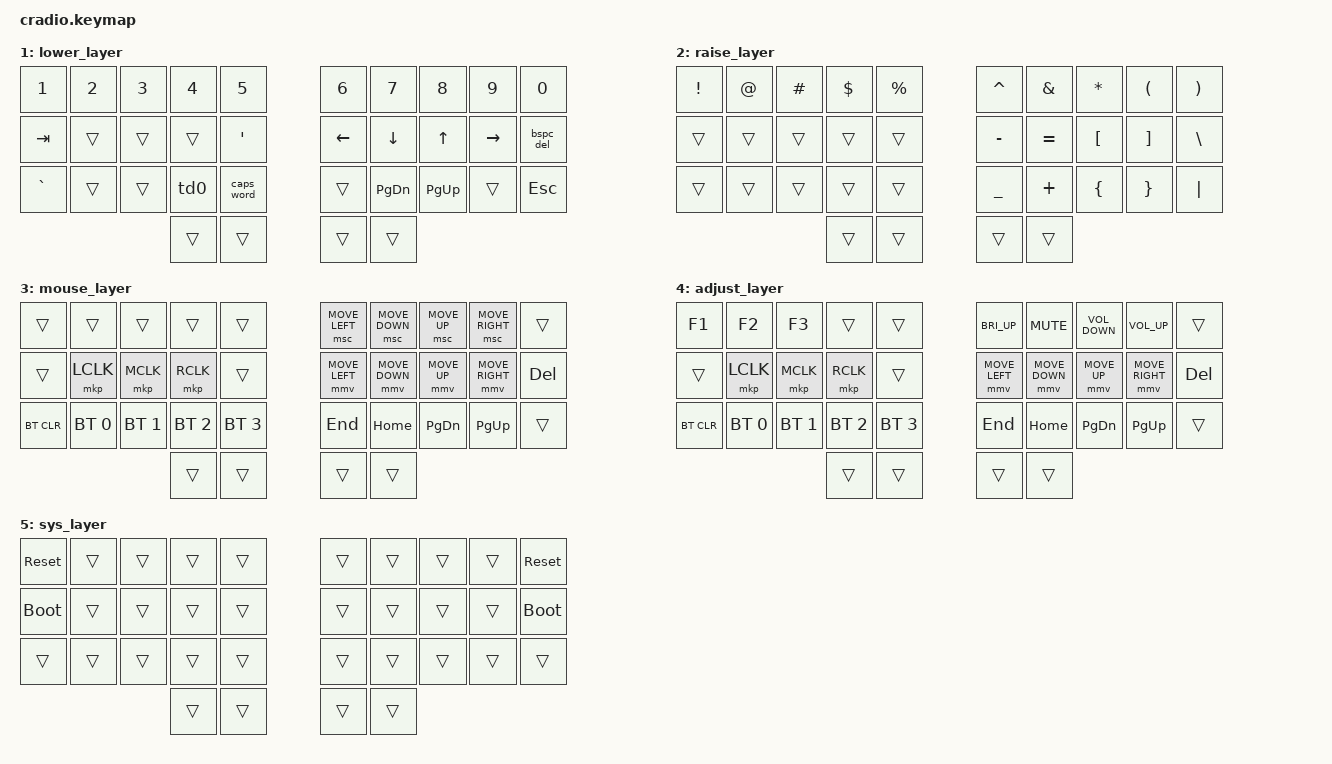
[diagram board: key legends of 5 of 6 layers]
// Copyright (c) 2022 The ZMK Contributors
// SPDX-License-Identifier: MIT

#include <behaviors.dtsi>
#include <dt-bindings/zmk/keys.h>
#include <dt-bindings/zmk/bt.h>
#include <dt-bindings/zmk/mouse.h>
#include <behaviors/mouse_keys.dtsi>

// Home row mods macro
#define HRML(k1,k2,k3,k4) &hm LCTRL k1  &hm LALT k2  &hm LGUI k3  &hm LSHIFT k4
#define HRMR(k1,k2,k3,k4) &hm RSHIFT k1  &hm RGUI k2  &hm RALT k3  &bhm RCTRL k4

/ {
    
    conditional_layers {
      compatible = "zmk,conditional-layers";
      tri_layer {
        if-layers = <1 2>;
        then-layer = <3>;
      };
    };

    combos {
      compatible = "zmk,combos";

      to_normal_keys_layer {
        bindings = <&tog 5>;
        key-positions = <17 18>; // g + h
      };

      // to_adjust_2_layer {
      //   bindings = <&mo 4>;
      //   key-positions = <40 34>;  // raise + z
      // };
    };

    behaviors {
      bhm: balanced_homerow_mods { // suitable for fast shortcuts/navigating
        compatible = "zmk,behavior-hold-tap";
        #binding-cells = <2>;
        tapping-term-ms = <200>;    // <---[[moderate duration]]
        quick-tap-ms = <0>;
        flavor = "balanced"; // The 'balanced' flavor will trigger the hold behavior when the tapping-term-ms has expired or another key is pressed and released.
        bindings = <&kp>, <&kp>;
      };

      hm: homerow_mods { // suitable for fast typing as this behavior prefers tap over than hold
        compatible = "zmk,behavior-hold-tap";
        #binding-cells = <2>;
        tapping-term-ms = <200>;
        quick-tap-ms = <0>;
        flavor = "tap-preferred"; // The 'tap-preferred' flavor triggers the hold behavior when the tapping-term-ms has expired. Pressing another key within tapping-term-ms does not affect the decision.
        bindings = <&kp>, <&kp>;
      };

      td0: tap_dance_0 {
        compatible = "zmk,behavior-tap-dance";
        #binding-cells = <0>;
        tapping-term-ms = <200>;
        bindings = <&kp ESC>, <&kp GLOBE>; // press once for Esc, and double for Globe/fn key
      };

      td1: tap_dance_1 {
        compatible = "zmk,behavior-tap-dance";
        #binding-cells = <0>;
        tapping-term-ms = <200>;
        bindings = <&mo 2>, <&mo 4>; // press once for "raise_layer", and double for "adjust_layer"
      };

      bspc_del: backspace_delete {
        compatible = "zmk,behavior-mod-morph";
        #binding-cells = <0>;
        bindings = <&kp BACKSPACE>, <&kp DELETE>;
        mods = <(MOD_LSFT|MOD_RSFT)>;
        keep-mods = <(MOD_RSFT)>;
      };

    };

    keymap {
        compatible = "zmk,keymap";
        default_layer {
            bindings = <
        //╭──────────┬──────────┬──────────┬──────────┬──────────╮   ╭──────────┬──────────┬──────────┬──────────┬──────────╮
        //│  Q       │  W       │  E       │  R       │  T       │   │  Y       │  U       │  I       │  O       │  P       │
            &kp Q      &kp W      &kp E      &kp R      &kp T          &kp Y      &kp U      &kp I      &kp O      &kp P
        //├──────────┼──────────┼──────────┼──────────┼──────────┤   ├──────────┼──────────┼──────────┼──────────┼──────────┤
        //│  A       │  S       │  D       │  F       │  G       │   │  H       │  J       │  K       │  L       │ ' "      │
            HRML(A,        S,         D,         F)     &kp G          &kp H      HRMR(J,        K,         L,        SQT)
        //├──────────┼──────────┼──────────┼──────────┼──────────┤   ├──────────┼──────────┼──────────┼──────────┼──────────┤
        //│  Z       │  X       │  C       │  V       │  B       │   │  N       │  M       │ , <      │ . >      │ / ?      │
            &kp Z      &kp X      &kp C      &kp V      &kp B          &kp N      &kp M      &kp COMMA  &kp DOT    &hm CAPS FSLH
        //╰──────────┴──────────┴──────────┼──────────┼──────────┤   ├──────────┼──────────┼──────────┴──────────┴──────────╯
                                              &mo 1     &kp SPACE      &kp ENTER    &td1
        //                                 ╰──────────┴──────────╯   ╰──────────┴──────────╯
            >;
        };

        lower_layer {
            bindings = <
        //╭──────────┬──────────┬──────────┬──────────┬──────────╮   ╭──────────┬──────────┬──────────┬──────────┬──────────╮
        //│ 1        │  2       │  3       │  4       │  5       │   │    6     │    7     │    8     │    9     │   0      │
            &kp N1     &kp N2     &kp N3     &kp N4     &kp N5         &kp N6     &kp N7     &kp N8     &kp N9     &kp N0
        //├──────────┼──────────┼──────────┼──────────┼──────────┤   ├──────────┼──────────┼──────────┼──────────┼──────────┤
        //│ TAB      │          │          │          │          │   │ LEFT     │ DOWN     │ UP       │ RIGHT    │  del     │
            &kp TAB    &trans     &trans     &trans     &kp SQT        &kp LEFT   &kp DOWN   &kp UP     &kp RIGHT  &bspc_del
        //├──────────┼──────────┼──────────┼──────────┼──────────┤   ├──────────┼──────────┼──────────┼──────────┼──────────┤
        //│ CAPS     │  7       │  8       │  9       │  0       │   │          │          │          │          │          │
           &kp GRAVE   &trans      &trans    &td0      &caps_word      &trans    &kp PAGE_DOWN  &kp PAGE_UP  &trans &kp ESC
        //╰──────────┴──────────┴──────────┼──────────┼──────────┤   ├──────────┼──────────┼──────────┴──────────┴──────────╯
                                             &trans     &trans         &trans     &trans
        //                                 ╰──────────┴──────────╯   ╰──────────┴──────────╯
            >;
        };

        raise_layer {
            bindings = <
        //╭──────────┬──────────┬──────────┬──────────┬──────────╮   ╭──────────┬──────────┬──────────┬──────────┬──────────╮
        //│  !       │  @       │  #       │  $       │  %       │   │  ^       │  &       │  *       │  (       │  )       │
            &kp EXCL  &kp AT     &kp HASH   &kp DLLR   &kp PRCNT      &kp CARET  &kp AMPS   &kp ASTRK  &kp LPAR   &kp RPAR
        //├──────────┼──────────┼──────────┼──────────┼──────────┤   ├──────────┼──────────┼──────────┼──────────┼──────────┤
        //│          │          │          │          │          │   │  -       │  =       │  [       │  ]       │  \       │
            &trans    &trans     &trans     &trans     &trans         &kp MINUS  &kp EQUAL  &kp LBKT   &kp RBKT   &kp BSLH
        //├──────────┼──────────┼──────────┼──────────┼──────────┤   ├──────────┼──────────┼──────────┼──────────┼──────────┤
        //│          │          │          │          │          │   │  _       │  +       │  {       │  }       │  |       │
            &trans    &trans     &trans     &trans     &trans         &kp UNDER  &kp PLUS   &kp LBRC   &kp RBRC   &kp PIPE
        //╰──────────┴──────────┴──────────┼──────────┼──────────┤   ├──────────┼──────────┼──────────┴──────────┴──────────╯
                                             &trans     &trans         &trans     &trans
        //                                 ╰──────────┴──────────╯   ╰──────────┴──────────╯
            >;
        };

        mouse_layer {
            bindings = <
        //╭──────────┬──────────────────┬──────────────────┬──────────────────┬──────────────╮   ╭────────────────┬────────────────┬────────────────┬────────────────┬──────────╮
        //│          │                  │                  │                  │              │   │                │                │                │                │          │
           &trans       &trans             &trans             &trans            &trans             &msc MOVE_LEFT   &msc MOVE_DOWN   &msc MOVE_UP     &msc MOVE_RIGHT  &trans
        //├──────────┼──────────────────┼──────────────────┼──────────────────┼──────────────┤   ├────────────────┼────────────────┼────────────────┼────────────────┼──────────┤
        //│          │                  │                  │                  │              │   │                │                │                │                │          │
           &trans       &mkp LCLK          &mkp MCLK          &mkp RCLK         &trans             &mmv MOVE_LEFT   &mmv MOVE_DOWN   &mmv MOVE_UP     &mmv MOVE_RIGHT  &kp DEL
        //├──────────┼──────────────────┼──────────────────┼──────────────────┼──────────────┤   ├────────────────┼────────────────┼────────────────┼────────────────┼──────────┤
        //│          │                  │                  │                  │              │   │                │                │                │                │          │
           &bt BT_CLR  &bt BT_SEL 0       &bt BT_SEL 1       &bt BT_SEL 2       &bt BT_SEL 3         &kp END        &kp HOME         &kp PAGE_DOWN    &kp PAGE_UP      &trans
        //╰──────────┴──────────────────┴──────────────────┼──────────────────┼──────────────┤   ├────────────────┼────────────────┼────────────────┴────────────────┴──────────╯
                                                                     &trans     &trans              &trans          &trans
        //                                                         ╰──────────┴──────────────╯   ╰────────────────┴──────────╯
            >;
        };

        adjust_layer {
            bindings = <
        //╭──────────┬──────────────────┬──────────────────┬──────────────────┬──────────────╮   ╭────────────────┬────────────────┬────────────────────┬────────────────────┬──────────╮
        //│          │                  │                  │                  │              │   │                │                │                    │                    │          │
            &kp F1     &kp F2             &kp F3             &trans             &trans             &kp C_BRI_UP     &kp C_MUTE       &kp C_VOLUME_DOWN    &kp C_VOLUME_UP       &trans
        //├──────────┼──────────────────┼──────────────────┼──────────────────┼──────────────┤   ├────────────────┼────────────────┼────────────────────┼────────────────────┼──────────┤
        //│          │                  │                  │                  │              │   │                │                │                    │                    │          │
           &trans       &mkp LCLK          &mkp MCLK          &mkp RCLK         &trans             &mmv MOVE_LEFT   &mmv MOVE_DOWN   &mmv MOVE_UP         &mmv MOVE_RIGHT      &kp DEL
        //├──────────┼──────────────────┼──────────────────┼──────────────────┼──────────────┤   ├────────────────┼────────────────┼────────────────────┼────────────────────┼──────────┤
        //│          │                  │                  │                  │              │   │                │                │                    │                    │          │
           &bt BT_CLR  &bt BT_SEL 0       &bt BT_SEL 1       &bt BT_SEL 2       &bt BT_SEL 3         &kp END        &kp HOME         &kp PAGE_DOWN        &kp PAGE_UP          &trans
        //╰──────────┴──────────────────┴──────────────────┼──────────────────┼──────────────┤   ├────────────────┼────────────────┼────────────────────┴────────────────────┴──────────╯
                                                                     &trans     &trans              &trans          &trans
        //                                                         ╰──────────┴──────────────╯   ╰────────────────┴──────────╯
            >;
        };


        sys_layer {
            bindings = <
        //╭──────────┬──────────┬──────────┬──────────┬──────────╮   ╭──────────┬──────────┬──────────┬──────────┬──────────╮
        //│ RESET    │          │          │          │          │   │          │          │          │          │  RESET   │
           &sys_reset  &trans     &trans     &trans    &trans          &trans     &trans     &trans     &trans    &sys_reset
        //├──────────┼──────────┼──────────┼──────────┼──────────┤   ├──────────┼──────────┼──────────┼──────────┼──────────┤
        //│BOOTLOADER│          │          │          │          │   │          │          │          │          │BOOTLOADER│
          &bootloader  &trans     &trans     &trans    &trans          &trans     &trans     &trans     &trans    &bootloader
        //├──────────┼──────────┼──────────┼──────────┼──────────┤   ├──────────┼──────────┼──────────┼──────────┼──────────┤
        //│          │          │          │          │          │   │          │          │          │          │          │
            &trans     &trans     &trans     &trans    &trans          &trans     &trans     &trans     &trans     &trans
        //╰──────────┴──────────┴──────────┼──────────┼──────────┤   ├──────────┼──────────┼──────────┴──────────┴──────────╯
                                             &trans     &trans         &trans     &trans
        //                                 ╰──────────┴──────────╯   ╰──────────┴──────────╯
            >;
        };
    };
};
